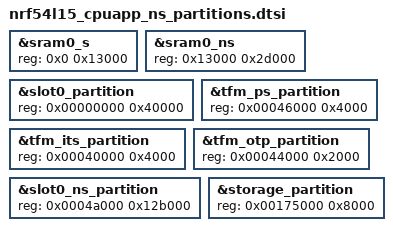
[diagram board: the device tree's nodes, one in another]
/*
 * Copyright (c) 2026 Nordic Semiconductor ASA
 *
 * SPDX-License-Identifier: LicenseRef-Nordic-5-Clause
 */

/* Match DTS-only partitioning to the Partition Manager split. */
&sram0_s {
	reg = <0x0 0x13000>;
	ranges = <0x0 0x0 0x13000>;
};

&sram0_ns {
	reg = <0x13000 0x2d000>;
	ranges = <0x0 0x13000 0x2d000>;
};

&slot0_partition {
	reg = <0x00000000 0x40000>;
};

&tfm_ps_partition {
	reg = <0x00046000 0x4000>;
};

&tfm_its_partition {
	reg = <0x00040000 0x4000>;
};

&tfm_otp_partition {
	reg = <0x00044000 0x2000>;
};

&slot0_ns_partition {
	reg = <0x0004a000 0x12b000>;
};

&storage_partition {
	reg = <0x00175000 0x8000>;
};
